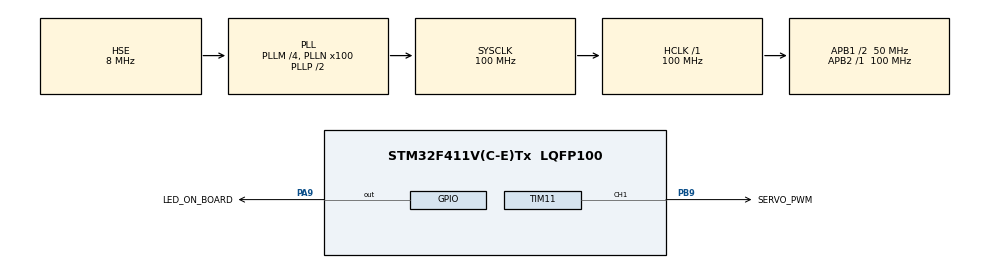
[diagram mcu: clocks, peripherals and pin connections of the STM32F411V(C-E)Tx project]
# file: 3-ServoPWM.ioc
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Mcu.Family=STM32F4
Mcu.Name=STM32F411V(C-E)Tx
Mcu.Package=LQFP100
NVIC.PriorityGroup=NVIC_PRIORITYGROUP_4
PA9.GPIO_Label=LED_ON_BOARD
PA9.Signal=GPIO_Output
PB9.GPIO_Label=SERVO_PWM
PB9.Signal=S_TIM11_CH1
PH0\ -\ OSC_IN.Mode=HSE-External-Oscillator
PH0\ -\ OSC_IN.Signal=RCC_OSC_IN
PH1\ -\ OSC_OUT.Mode=HSE-External-Oscillator
PH1\ -\ OSC_OUT.Signal=RCC_OSC_OUT
ProjectManager.HeapSize=0x200
ProjectManager.StackSize=0x400
ProjectManager.TargetToolchain=STM32CubeIDE
RCC.48MHZClocksFreq_Value=50000000
RCC.AHBFreq_Value=100000000
RCC.APB1CLKDivider=RCC_HCLK_DIV2
RCC.APB1Freq_Value=50000000
RCC.APB1TimFreq_Value=100000000
RCC.APB2Freq_Value=100000000
RCC.APB2TimFreq_Value=100000000
RCC.CortexFreq_Value=100000000
RCC.HCLKFreq_Value=100000000
RCC.HSE_VALUE=8000000
RCC.HSI_VALUE=16000000
RCC.LSE_VALUE=32768
RCC.PLLM=4
RCC.PLLN=100
RCC.PLLSourceVirtual=RCC_PLLSOURCE_HSE
RCC.SYSCLKFreq_VALUE=100000000
RCC.SYSCLKSource=RCC_SYSCLKSOURCE_PLLCLK
RCC.VCOOutputFreq_Value=200000000
SH.S_TIM11_CH1.0=TIM11_CH1,PWM Generation1 CH1
TIM11.AutoReloadPreload=TIM_AUTORELOAD_PRELOAD_ENABLE
TIM11.Channel=TIM_CHANNEL_1
TIM11.Period=19999
TIM11.Prescaler=99
VP_TIM11_VS_ClockSourceINT.Mode=Enable_Timer
board=custom

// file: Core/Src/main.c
/* USER CODE BEGIN Header */
/**
  ******************************************************************************
  * @file           : main.c
  * @brief          : Main program body
  ******************************************************************************
  * @attention
  *
  * Copyright (c) 2025 STMicroelectronics.
  * All rights reserved.
  *
  * This software is licensed under terms that can be found in the LICENSE file
  * in the root directory of this software component.
  * If no LICENSE file comes with this software, it is provided AS-IS.
  *
  ******************************************************************************
  */
/* USER CODE END Header */
#include "main.h"

TIM_HandleTypeDef htim11;

void SystemClock_Config(void);
static void MX_GPIO_Init(void);
static void MX_TIM11_Init(void);

int main(void)
{

  /* MCU Configuration--------------------------------------------------------*/

  /* Reset of all peripherals, Initializes the Flash interface and the Systick. */
  HAL_Init();

  /* Configure the system clock */
  SystemClock_Config();

  /* Initialize all configured peripherals */
  MX_GPIO_Init();
  MX_TIM11_Init();
  /* USER CODE BEGIN 2 */
  HAL_TIM_PWM_Start(&htim11, TIM_CHANNEL_1);
  /* USER CODE END 2 */

  /* Infinite loop */
  /* USER CODE BEGIN WHILE */
  while(1)
    {
	  		/* USER CODE BEGIN 3 */
    /* USER CODE END WHILE */

    /* USER CODE BEGIN 3 */
    /* USER CODE END WHILE */

    /* USER CODE BEGIN 3 */
    /* USER CODE END WHILE */

    /* USER CODE BEGIN 3 */
    /* USER CODE END WHILE */

    /* USER CODE BEGIN 3 */
	  htim11.Instance->CCR1 = 0;
//  	  __HAL_TIM_SET_COMPARE(&htim11, TIM_CHANNEL_1, 0);
  		HAL_Delay(1000);

  	  htim11.Instance->CCR1 = 1000;
//  		__HAL_TIM_SET_COMPARE(&htim11, TIM_CHANNEL_1, 1000);
  		HAL_Delay(1000);

  	  htim11.Instance->CCR1 = 2000;
//  		__HAL_TIM_SET_COMPARE(&htim11, TIM_CHANNEL_1, 2000);
  		HAL_Delay(1000);

		HAL_GPIO_TogglePin(LED_ON_BOARD_GPIO_Port, LED_ON_BOARD_Pin);
		HAL_Delay(1000);
		HAL_GPIO_TogglePin(LED_ON_BOARD_GPIO_Port, LED_ON_BOARD_Pin);
		HAL_Delay(1000);
        /* USER CODE END WHILE */
      }
  /* USER CODE END 3 */
}

void SystemClock_Config(void)
{
  RCC_OscInitTypeDef RCC_OscInitStruct = {0};
  RCC_ClkInitTypeDef RCC_ClkInitStruct = {0};

  /** Configure the main internal regulator output voltage
  */
  __HAL_RCC_PWR_CLK_ENABLE();
  __HAL_PWR_VOLTAGESCALING_CONFIG(PWR_REGULATOR_VOLTAGE_SCALE1);

  /** Initializes the RCC Oscillators according to the specified parameters
  * in the RCC_OscInitTypeDef structure.
  */
  RCC_OscInitStruct.OscillatorType = RCC_OSCILLATORTYPE_HSE;
  RCC_OscInitStruct.HSEState = RCC_HSE_ON;
  RCC_OscInitStruct.PLL.PLLState = RCC_PLL_ON;
  RCC_OscInitStruct.PLL.PLLSource = RCC_PLLSOURCE_HSE;
  RCC_OscInitStruct.PLL.PLLM = 4;
  RCC_OscInitStruct.PLL.PLLN = 100;
  RCC_OscInitStruct.PLL.PLLP = RCC_PLLP_DIV2;
  RCC_OscInitStruct.PLL.PLLQ = 4;
  if (HAL_RCC_OscConfig(&RCC_OscInitStruct) != HAL_OK)
  {
    Error_Handler();
  }

  /** Initializes the CPU, AHB and APB buses clocks
  */
  RCC_ClkInitStruct.ClockType = RCC_CLOCKTYPE_HCLK|RCC_CLOCKTYPE_SYSCLK
                              |RCC_CLOCKTYPE_PCLK1|RCC_CLOCKTYPE_PCLK2;
  RCC_ClkInitStruct.SYSCLKSource = RCC_SYSCLKSOURCE_PLLCLK;
  RCC_ClkInitStruct.AHBCLKDivider = RCC_SYSCLK_DIV1;
  RCC_ClkInitStruct.APB1CLKDivider = RCC_HCLK_DIV2;
  RCC_ClkInitStruct.APB2CLKDivider = RCC_HCLK_DIV1;

  if (HAL_RCC_ClockConfig(&RCC_ClkInitStruct, FLASH_LATENCY_3) != HAL_OK)
  {
    Error_Handler();
  }
}

static void MX_TIM11_Init(void)
{

  TIM_OC_InitTypeDef sConfigOC = {0};

  htim11.Instance = TIM11;
  htim11.Init.Prescaler = 99;
  htim11.Init.CounterMode = TIM_COUNTERMODE_UP;
  htim11.Init.Period = 19999;
  htim11.Init.ClockDivision = TIM_CLOCKDIVISION_DIV1;
  htim11.Init.AutoReloadPreload = TIM_AUTORELOAD_PRELOAD_ENABLE;
//  if (HAL_TIM_Base_Init(&htim11) != HAL_OK)
//  {
//    Error_Handler();
//  }
  if (HAL_TIM_PWM_Init(&htim11) != HAL_OK)
  {
    Error_Handler();
  }
  sConfigOC.OCMode = TIM_OCMODE_PWM1;
  sConfigOC.Pulse = 0;
  sConfigOC.OCPolarity = TIM_OCPOLARITY_HIGH;
  sConfigOC.OCFastMode = TIM_OCFAST_DISABLE;
  if (HAL_TIM_PWM_ConfigChannel(&htim11, &sConfigOC, TIM_CHANNEL_1) != HAL_OK)
  {
    Error_Handler();
  }
  HAL_TIM_MspPostInit(&htim11);

}

static void MX_GPIO_Init(void)
{
  GPIO_InitTypeDef GPIO_InitStruct = {0};

  /* GPIO Ports Clock Enable */
  __HAL_RCC_GPIOH_CLK_ENABLE();
  __HAL_RCC_GPIOA_CLK_ENABLE();
  __HAL_RCC_GPIOB_CLK_ENABLE();

  /*Configure GPIO pin Output Level */
  HAL_GPIO_WritePin(LED_ON_BOARD_GPIO_Port, LED_ON_BOARD_Pin, GPIO_PIN_RESET);

  /*Configure GPIO pin : LED_ON_BOARD_Pin (PA9) */
  GPIO_InitStruct.Pin = LED_ON_BOARD_Pin;
  GPIO_InitStruct.Mode = GPIO_MODE_OUTPUT_PP;
  GPIO_InitStruct.Pull = GPIO_NOPULL;
  GPIO_InitStruct.Speed = GPIO_SPEED_FREQ_LOW;
  HAL_GPIO_Init(LED_ON_BOARD_GPIO_Port, &GPIO_InitStruct);

  /* === ĐOẠN CODE THÊM VÀO ĐỂ SỬA LỖI === */
  /*Configure GPIO pin : SERVO_PWM_Pin (PB9) */
  GPIO_InitStruct.Pin = SERVO_PWM_Pin;
  GPIO_InitStruct.Mode = GPIO_MODE_AF_PP; // Chế độ Alternate Function Push-Pull
  GPIO_InitStruct.Pull = GPIO_NOPULL;
  GPIO_InitStruct.Speed = GPIO_SPEED_FREQ_LOW;
  GPIO_InitStruct.Alternate = GPIO_AF3_TIM11; // Kết nối chân này với TIM11
  HAL_GPIO_Init(SERVO_PWM_GPIO_Port, &GPIO_InitStruct);
  /* ======================================= */
}

void Error_Handler(void)
{
  __disable_irq();
  while (1)
  {
  }
}
